# wiz16b8m4ct3_0_WIZ16B8M4CT3 register map
Vendor: Texas Instruments
Registers are 32-bit, read-write, reset 0x0 unless marked. A register's access mark holds for its fields unless they carry their own. Offsets are as the file gives them; [hi:lo] are bit positions.

## wiz16b8m4ct3_0_WIZ16B8M4CT3 (part 9 of 12)
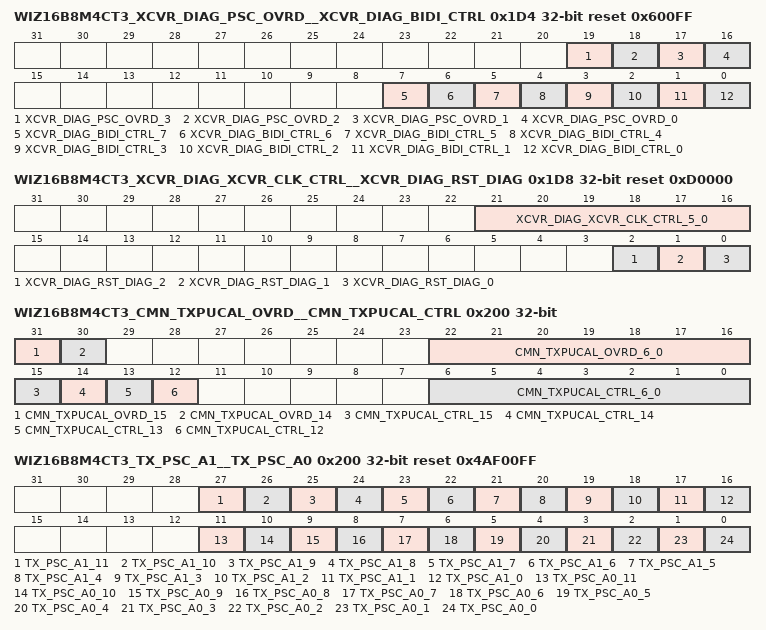
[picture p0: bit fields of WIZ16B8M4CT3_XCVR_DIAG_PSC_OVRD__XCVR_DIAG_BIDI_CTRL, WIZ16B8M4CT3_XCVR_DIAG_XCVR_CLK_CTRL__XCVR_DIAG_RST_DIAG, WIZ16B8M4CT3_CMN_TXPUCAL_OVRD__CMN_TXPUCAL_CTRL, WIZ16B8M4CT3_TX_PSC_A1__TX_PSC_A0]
0x1D4 WIZ16B8M4CT3_XCVR_DIAG_PSC_OVRD__XCVR_DIAG_BIDI_CTRL reset 0x600FF
  [19] XCVR_DIAG_PSC_OVRD_3 — Receiver DFE enable mask value standard mode 3: This bit will controls the rx_dfe_eq_enable_std_mask digital signal, which can be used to mask off the rxda_dfe_eq_enable signal coming from the power state controller and going into the analog, when xcvr_standard_mode is set to 2'b11. 1'b0 : The signal will be masked off. 1'b1 : The signal to pass through unchanged.
  [18] XCVR_DIAG_PSC_OVRD_2 — Receiver DFE enable mask value standard mode 2: This bit will controls the rx_dfe_eq_enable_std_mask digital signal, which can be used to mask off the rxda_dfe_eq_enable signal coming from the power state controller and going into the analog, when xcvr_standard_mode is set to 2'b10. 1'b0 : The signal will be masked off. 1'b1 : The signal to pass through unchanged.
  [17] XCVR_DIAG_PSC_OVRD_1 — Receiver DFE enable mask value standard mode 1: This bit will controls the rx_dfe_eq_enable_std_mask digital signal, which can be used to mask off the rxda_dfe_eq_enable signal coming from the power state controller and going into the analog, when xcvr_standard_mode is set to 2'b01. 1'b0 : The signal will be masked off. 1'b1 : The signal to pass through unchanged.
  [16] XCVR_DIAG_PSC_OVRD_0 — Receiver DFE enable mask value standard mode 0: This bit will controls the rx_dfe_eq_enable_std_mask digital signal, which can be used to mask off the rxda_dfe_eq_enable signal coming from the power state controller and going into the analog, when xcvr_standard_mode is set to 2'b00. 1'b0 : The signal will be masked off. 1'b1 : The signal to pass through unchanged.
  [7] XCVR_DIAG_BIDI_CTRL_7 — Receiver enable standard mode 3: When bidirectional bumps are implemented in the transceiver, this bit is a global enable for the receiver function, when xcvr_standard_mode is set to 2'b11. When bidirectional bumps are not implemented, this bit will be reset to 1'b1, and should not be changed. When bidirectional bumps are implemented in the transceiver, this bit and the corresponding transmitter enable bit must not be set to 1'b1 at the same time. 1'b0 : RX disabled 1'b1 : RX enabled
  [6] XCVR_DIAG_BIDI_CTRL_6 — Receiver enable standard mode 2: When bidirectional bumps are implemented in the transceiver, this bit is a global enable for the receiver function, when xcvr_standard_mode is set to 2'b10. When bidirectional bumps are not implemented, this bit will be reset to 1'b1, and should not be changed. When bidirectional bumps are implemented in the transceiver, this bit and the corresponding transmitter enable bit must not be set to 1'b1 at the same time. 1'b0 : RX disabled 1'b1 : RX enabled
  [5] XCVR_DIAG_BIDI_CTRL_5 — Receiver enable standard mode 1: When bidirectional bumps are implemented in the transceiver, this bit is a global enable for the receiver function, when xcvr_standard_mode is set to 2'b01. When bidirectional bumps are not implemented, this bit will be reset to 1'b1, and should not be changed. When bidirectional bumps are implemented in the transceiver, this bit and the corresponding transmitter enable bit must not be set to 1'b1 at the same time. 1'b0 : RX disabled 1'b1 : RX enabled
  [4] XCVR_DIAG_BIDI_CTRL_4 — Receiver enable standard mode 0: When bidirectional bumps are implemented in the transceiver, this bit is a global enable for the receiver function, when xcvr_standard_mode is set to 2'b00. When bidirectional bumps are not implemented, this bit will be reset to 1'b1, and should not be changed. When bidirectional bumps are implemented in the transceiver, this bit and the corresponding transmitter enable bit must not be set to 1'b1 at the same time. 1'b0 : RX disabled 1'b1 : RX enabled
  [3] XCVR_DIAG_BIDI_CTRL_3 — Transmitter enable standard mode 3: When bidirectional bumps are implemented in the transceiver, this bit is a global enable for the transmitter function, when xcvr_standard_mode is set to 2'b11. When bidirectional bumps are not implemented, this bit will be reset to 1'b1, and should not be changed. When bidirectional bumps are implemented in the transceiver, this bit and the corresponding receiver enable bit must not be set to 1'b1 at the same time. 1'b0 : TX disabled 1'b1 : TX enabled
  [2] XCVR_DIAG_BIDI_CTRL_2 — Transmitter enable standard mode 2: When bidirectional bumps are implemented in the transceiver, this bit is a global enable for the transmitter function, when xcvr_standard_mode is set to 2'b10. When bidirectional bumps are not implemented, this bit will be reset to 1'b1, and should not be changed. When bidirectional bumps are implemented in the transceiver, this bit and the corresponding receiver enable bit must not be set to 1'b1 at the same time. 1'b0 : TX disabled 1'b1 : TX enabled
  [1] XCVR_DIAG_BIDI_CTRL_1 — Transmitter enable standard mode 1: When bidirectional bumps are implemented in the transceiver, this bit is a global enable for the transmitter function, when xcvr_standard_mode is set to 2'b01. When bidirectional bumps are not implemented, this bit will be reset to 1'b1, and should not be changed. When bidirectional bumps are implemented in the transceiver, this bit and the corresponding receiver enable bit must not be set to 1'b1 at the same time. 1'b0 : TX disabled 1'b1 : TX enabled
  [0] XCVR_DIAG_BIDI_CTRL_0 — Transmitter enable standard mode 0: When bidirectional bumps are implemented in the transceiver, this bit is a global enable for the transmitter function, when xcvr_standard_mode is set to 2'b00. When bidirectional bumps are not implemented, this bit will be reset to 1'b1, and should not be changed. When bidirectional bumps are implemented in the transceiver, this bit and the corresponding receiver enable bit must not be set to 1'b1 at the same time. 1'b0 : TX disabled 1'b1 : TX enabled
0x1D8 WIZ16B8M4CT3_XCVR_DIAG_XCVR_CLK_CTRL__XCVR_DIAG_RST_DIAG access per field reset 0xD0000
  [21:16] XCVR_DIAG_XCVR_CLK_CTRL_5_0 rw — Transceiver clock enable delay timer value: This specifies the number of xcvr_psm_clk clock cycles that the transceiver high speed clock reset release state machine will wait between when it drives the analog transceiver clock enable signal active, and when it will initiate the process to release the reset for this clock. The default value of this register corresponds to a delay of at least 100 nSec.
  [2] XCVR_DIAG_RST_DIAG_2 ro — Current state of the tx_coef_calc_reset_n reset.
  [1] XCVR_DIAG_RST_DIAG_1 ro — Current state of the xcvr_psm_reset_n reset.
  [0] XCVR_DIAG_RST_DIAG_0 ro — Current state of the xcvr_ref_clk_reset_n reset.
0x1DC WIZ16B8M4CT3_XCVR_DIAG_DCYA
  [31:16] XCVR_DIAG_DCYA_15_0 — Reserved - spare
0x1F8 WIZ16B8M4CT3_DTB_MUX_SEL
  [4:0] DTB_MUX_SEL — See cadence documentation on digital test bus.
0x1FC WIZ16B8M4CT3_DIAG_TEST
  [31:0] DIAG_REG — Diagnostic register. This register allows full read/write of all data bits to be tested.
0x200 WIZ16B8M4CT3_CMN_TXPUCAL_OVRD__CMN_TXPUCAL_CTRL access per field
  [31] CMN_TXPUCAL_OVRD_15 rw — Resistor code override enable: Activation (1'b1) of this register bit allows the resistor codes determined during the automatic resistor calibration process to be overridden. The override value is specified using the resistor code override value field of this register.
  [30] CMN_TXPUCAL_OVRD_14 rw — Analog calibration enable override: Activation (1'b1) of this register bit will force the analog calibration circuits to be enabled by activating the cmnda_rescal_en_tx_useg enable and the cmnda_rescal_clk_tx_useg clock.
  [22:16] CMN_TXPUCAL_OVRD_6_0 rw — Resistor code override value: These bits are used to override the resistor code determined during the automatic resistor calibration process. The resistor code written to these bits is valid when the resistor code override enable bit in this register is active. The following are the values for the code. 7'b0000000: No resistors active. 7'b0000001: 1 resistor active. 7'b0000010: 2 resistors active. 7'b0000011: 3 resistors active. 7'b0000100: 4 resistors active. ... 7'b0111100: 60 resistors active. Note: The most significant bit is the calibration code sign bit, and is always 1'b0 in this application.
  [15] CMN_TXPUCAL_CTRL_15 rw — Start resistor calibration: Activating (1'b1) this bit will start the resistor calibration process. This signal must remain active until the resistor calibration process is complete. To start another resistor calibration process, this register must first be set inactive (1'b0) until the resistor calibration process done bit in this register is cleared. Note: This signal is intended to be for diagnostics purposes only. This calibration process is automatically activated internally by the startup state machine. When using this bit, the user must wait until after the internally activated process completes.
  [14] CMN_TXPUCAL_CTRL_14 ro — Resistor calibration process done: This bit will be set to 1'b1 when the resistor calibration process is complete. It will be cleared by cmn_reset_n, or by the deactivation of the start resistor calibration bit in this register after calibration is complete. Note: This bit is intended to be for diagnostics purposes only. Note: This bit is not likely to be observed as being set after internal automatic calibration is complete, because the internally generated run signal will be driven inactive immediately after the done signal is activated, and therefore the internal done signal will be cleared. Note: Three cmn_ref_clk cycles are required after the start of the resistor calibration process to clear this signal.
  [13] CMN_TXPUCAL_CTRL_13 ro — No analog calibration response : This signal indicates that the calibration function has gone through the entire calibration process, reached the final calibration value, and the analog has not responded indicating that a valid calibration value has been reached. Note: Due to the nature of the calibration process, it is not possible to determine if the analog responded or not for the lowest code of 7'b0000000. The reason for this is, when sequencing to lower codes, the calibration function is looking for the analog response to transition from 1'b1 to 1'b0. If the lowest calibration code is the correct code, the analog will respond with 1'b1, and the algorithm can't sequence to a lower code to look for the transition from 1'b1 to 1'b0. Similarly, if the analog is not responding, it is not possible to sequence to a lower code to detect this. Therefore, even when the calibration function selects this calibration code as valid, this bit will be set.
  [12] CMN_TXPUCAL_CTRL_12 ro — Current analog comparator response: This is the current state of the analog comparator response signal (cmnda_rescal_comp_tx_useg). This signal is not synchronized, and is provided for diagnostic purposes only.
  [6:0] CMN_TXPUCAL_CTRL_6_0 ro — Resistor calibration code: This is the calibration code that was determined by the resistor calibration process. The following are the values for the code. 7'b0000000: No resistors active. 7'b0000001: 1 resistor active. 7'b0000010: 2 resistors active. 7'b0000011: 3 resistors active. 7'b0000100: 4 resistors active. ... 7'b0111100: 60 resistors active. Note: The most significant bit is the calibration code sign bit, and is always 1'b0 in this application. Note: The reset value for this field is with the common calibration power island switched off. In cases where this power island is switched on, the reset value be 7'b0101101.
0x200 WIZ16B8M4CT3_TX_PSC_A1__TX_PSC_A0 reset 0x4AF00FF
  [27] TX_PSC_A1_11 — TX driver common mode enable extend control
  [26] TX_PSC_A1_10 — Force txda_lfps_sel active
  [25] TX_PSC_A1_9 — LFPS clock gate enable
  [24] TX_PSC_A1_8 — Reserved - spare
  [23] TX_PSC_A1_7 — Transmitter low current mode
  [22] TX_PSC_A1_6 — Transmitter mission mode enable
  [21] TX_PSC_A1_5 — TX driver common mode enable
  [20] TX_PSC_A1_4 — TX driver enable
  [19] TX_PSC_A1_3 — TX post-emphasis enable (C+1)
  [18] TX_PSC_A1_2 — TX pre-emphasis enable (C-1)
  [17] TX_PSC_A1_1 — TX pre-driver enable
  [16] TX_PSC_A1_0 — TX serializer enable
  [11] TX_PSC_A0_11 — TX driver common mode enable extend control: Specifies which power states the tx_cmn_mode_en_ext signal is considered valid in and can be used to force the driver to continue to be in the common mode state.
  [10] TX_PSC_A0_10 — Force txda_lfps_sel active: Setting this bit forces the txda_lfps_sel signal going to the analog to be driven active. Note: This function is implemented for additional power savings. In the analog, this signal controls a MUX select associated with the driver. Setting this bit to 1'b1 will force the MUX to select the LFPS data path. By selecting this path in low power states, instead of the serializer path, the driver inputs will be driven to 1'b0, instead of having the potential to toggle.
  [9] TX_PSC_A0_9 — LFPS clock gate enable: Enables the LFPS clock gate when an LFPS clock is required.
  [8] TX_PSC_A0_8 — Reserved - spare
  [7] TX_PSC_A0_7 — Transmitter low current mode: Enables a low current consumption mode within the common mode voltage circuit in the driver, via the txda_drv_idle_lowi_en signal going to the analog.
  [6] TX_PSC_A0_6 — Transmitter mission mode enable: Enables the analog circuits in the driver required to run in mission mode, via the txda_drv_mission_en signal going to the analog.
  [5] TX_PSC_A0_5 — TX driver common mode enable: Enables the common mode voltage circuits in the driver.
  [4] TX_PSC_A0_4 — TX driver enable: Enables the transmitter driver, via the H bridge driver controller.
  [3] TX_PSC_A0_3 — TX post-emphasis enable (C+1): Enables the transmitter circuits related to the post-emphasis function.
  [2] TX_PSC_A0_2 — TX pre-emphasis enable (C-1): Enables the transmitter circuits related to the pre-emphasis function.
  [1] TX_PSC_A0_1 — TX pre-driver enable: Enables the transmitter pre-driver, driver data selection MUX, and receiver detect.
  [0] TX_PSC_A0_0 — TX serializer enable: Enables the serializer and related clock divider circuits.
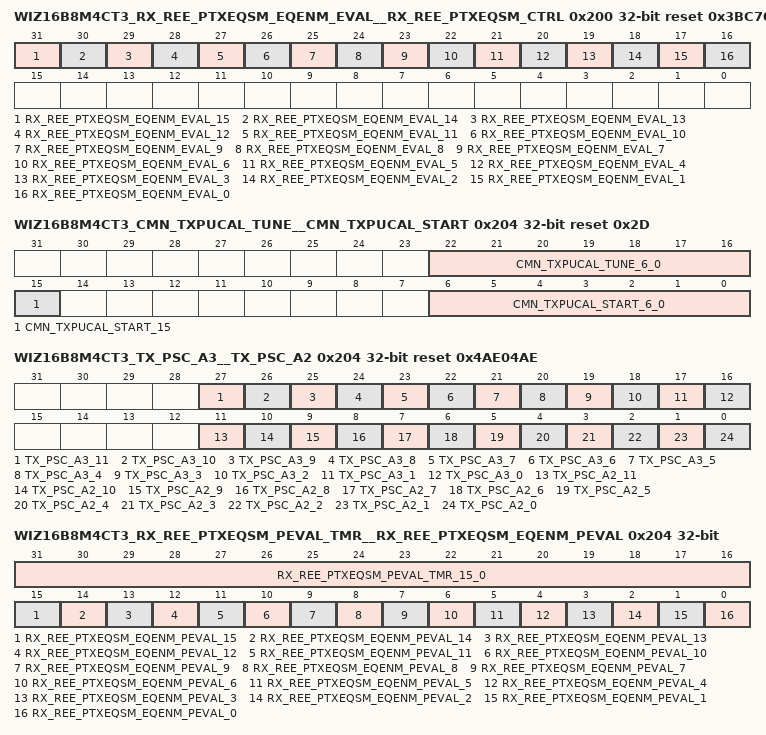
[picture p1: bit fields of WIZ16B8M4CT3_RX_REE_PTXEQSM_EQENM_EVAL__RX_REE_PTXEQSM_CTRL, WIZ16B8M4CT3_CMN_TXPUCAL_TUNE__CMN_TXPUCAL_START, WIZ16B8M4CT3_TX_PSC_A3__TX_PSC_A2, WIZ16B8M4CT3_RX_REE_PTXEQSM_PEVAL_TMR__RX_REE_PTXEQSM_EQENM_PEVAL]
0x200 WIZ16B8M4CT3_RX_REE_PTXEQSM_EQENM_EVAL__RX_REE_PTXEQSM_CTRL reset 0x3BC70000
  [31] RX_REE_PTXEQSM_EQENM_EVAL_15 — Reserved - spare
  [30] RX_REE_PTXEQSM_EQENM_EVAL_14 — Ignore 1010 controller : When set to 1'b1, this function is enabled when the PCIe TX equalization control state machine is controlling the REE.
  [29] RX_REE_PTXEQSM_EQENM_EVAL_13 — TX equalization evaluator : When set to 1'b1, this function is enabled when the PCIe TX equalization control state machine is controlling the REE.
  [28] RX_REE_PTXEQSM_EQENM_EVAL_12 — TX post cursor control : When set to 1'b1, this function is enabled when the PCIe TX equalization control state machine is controlling the REE.
  [27] RX_REE_PTXEQSM_EQENM_EVAL_11 — TX pre cursor control : When set to 1'b1, this function is enabled when the PCIe TX equalization control state machine is controlling the REE.
  [26] RX_REE_PTXEQSM_EQENM_EVAL_10 — Short channel correction : When set to 1'b1, this function is enabled when the TX equalization general control state machine is controlling the REE.
  [25] RX_REE_PTXEQSM_EQENM_EVAL_9 — RX attenuation : When set to 1'b1, this function is enabled when the PCIe TX equalization control state machine is controlling the REE.
  [24] RX_REE_PTXEQSM_EQENM_EVAL_8 — RX VGA gain : When set to 1'b1, this function is enabled when the PCIe TX equalization control state machine is controlling the REE.
  [23] RX_REE_PTXEQSM_EQENM_EVAL_7 — RX offset correction coefficient : When set to 1'b1, this function is enabled when the PCIe TX equalization control state machine is controlling the REE.
  [22] RX_REE_PTXEQSM_EQENM_EVAL_6 — RX peaking amp gain : When set to 1'b1, this function is enabled when the PCIe TX equalization control state machine is controlling the REE.
  [21] RX_REE_PTXEQSM_EQENM_EVAL_5 — RX low frequency equalizer adaptive control : When set to 1'b1, this function is enabled when the PCIe TX equalization control state machine is controlling the REE.
  [20] RX_REE_PTXEQSM_EQENM_EVAL_4 — Reserved - spare
  [19] RX_REE_PTXEQSM_EQENM_EVAL_3 — Reserved - spare
  [18] RX_REE_PTXEQSM_EQENM_EVAL_2 — RX tap 3 : When set to 1'b1, this function is enabled when the PCIe TX equalization control state machine is controlling the REE.
  [17] RX_REE_PTXEQSM_EQENM_EVAL_1 — RX tap 2 : When set to 1'b1, this function is enabled when the PCIe TX equalization control state machine is controlling the REE.
  [16] RX_REE_PTXEQSM_EQENM_EVAL_0 — RX tap 1 : When set to 1'b1, this function is enabled when the PCIe TX equalization control state machine is controlling the REE.
0x204 WIZ16B8M4CT3_CMN_TXPUCAL_TUNE__CMN_TXPUCAL_START reset 0x2D
  [22:16] CMN_TXPUCAL_TUNE_6_0 — Resistor calibration tune value: The value of this field is added to the automatically calibrated code, or the override code if override is enabled. Note: This value is a twos complement value, so the calibrated code can be increased or decreased.
  [15] CMN_TXPUCAL_START_15 — Resistor calibration direction: This controls the direction that the automatic calibration process steps the calibration codes in. 1'b0 : From 7'b0000000 to 7'b0111100. 1'b1 : From 7'b0111100 to 7'b0000000.
  [6:0] CMN_TXPUCAL_START_6_0 — Start resistor calibration code: This is the calibration code that the resistor calibration process starts with when automatic calibration is run. The following are the values for the code. 7'b0000000: No resistors active. 7'b0000001: 1 resistor active. 7'b0000010: 2 resistors active. 7'b0000011: 3 resistors active. 7'b0000100: 4 resistors active. ... 7'b0111100: 60 resistors active. Note: The most significant bit is the calibration code sign bit, and is always 1'b0 in this application.
0x204 WIZ16B8M4CT3_TX_PSC_A3__TX_PSC_A2 reset 0x4AE04AE
  [27] TX_PSC_A3_11 — TX driver common mode enable extend control
  [26] TX_PSC_A3_10 — Force txda_lfps_sel active
  [25] TX_PSC_A3_9 — LFPS clock gate enable
  [24] TX_PSC_A3_8 — Reserved - spare
  [23] TX_PSC_A3_7 — Transmitter low current mode
  [22] TX_PSC_A3_6 — Transmitter mission mode enable
  [21] TX_PSC_A3_5 — TX driver common mode enable
  [20] TX_PSC_A3_4 — TX driver enable
  [19] TX_PSC_A3_3 — TX post-emphasis enable (C+1)
  [18] TX_PSC_A3_2 — TX pre-emphasis enable (C-1)
  [17] TX_PSC_A3_1 — TX pre-driver enable
  [16] TX_PSC_A3_0 — TX serializer enable
  [11] TX_PSC_A2_11 — TX driver common mode enable extend control
  [10] TX_PSC_A2_10 — Force txda_lfps_sel active
  [9] TX_PSC_A2_9 — LFPS clock gate enable
  [8] TX_PSC_A2_8 — Reserved - spare
  [7] TX_PSC_A2_7 — Transmitter low current mode
  [6] TX_PSC_A2_6 — Transmitter mission mode enable
  [5] TX_PSC_A2_5 — TX driver common mode enable
  [4] TX_PSC_A2_4 — TX driver enable
  [3] TX_PSC_A2_3 — TX post-emphasis enable (C+1)
  [2] TX_PSC_A2_2 — TX pre-emphasis enable (C-1)
  [1] TX_PSC_A2_1 — TX pre-driver enable
  [0] TX_PSC_A2_0 — TX serializer enable
0x204 WIZ16B8M4CT3_RX_REE_PTXEQSM_PEVAL_TMR__RX_REE_PTXEQSM_EQENM_PEVAL
  [31:16] RX_REE_PTXEQSM_PEVAL_TMR_15_0 — Run post evaluation equalization timer value : This specifies number of clock cycles the state machine will wait in the Post Evaluation Equalization state.
  [15] RX_REE_PTXEQSM_EQENM_PEVAL_15 — Reserved - spare
  [14] RX_REE_PTXEQSM_EQENM_PEVAL_14 — Ignore 1010 controller : When set to 1'b1, this function is enabled when the PCIe TX equalization control state machine is controlling the REE.
  [13] RX_REE_PTXEQSM_EQENM_PEVAL_13 — TX equalization evaluator : When set to 1'b1, this function is enabled when the PCIe TX equalization control state machine is controlling the REE.
  [12] RX_REE_PTXEQSM_EQENM_PEVAL_12 — TX post cursor control : When set to 1'b1, this function is enabled when the PCIe TX equalization control state machine is controlling the REE.
  [11] RX_REE_PTXEQSM_EQENM_PEVAL_11 — TX pre cursor control : When set to 1'b1, this function is enabled when the PCIe TX equalization control state machine is controlling the REE.
  [10] RX_REE_PTXEQSM_EQENM_PEVAL_10 — Short channel correction : When set to 1'b1, this function is enabled when the TX equalization general control state machine is controlling the REE.
  [9] RX_REE_PTXEQSM_EQENM_PEVAL_9 — RX attenuation : When set to 1'b1, this function is enabled when the PCIe TX equalization control state machine is controlling the REE.
  [8] RX_REE_PTXEQSM_EQENM_PEVAL_8 — RX VGA gain : When set to 1'b1, this function is enabled when the PCIe TX equalization control state machine is controlling the REE.
  [7] RX_REE_PTXEQSM_EQENM_PEVAL_7 — RX offset correction coefficient : When set to 1'b1, this function is enabled when the PCIe TX equalization control state machine is controlling the REE.
  [6] RX_REE_PTXEQSM_EQENM_PEVAL_6 — RX peaking amp gain : When set to 1'b1, this function is enabled when the PCIe TX equalization control state machine is controlling the REE.
  [5] RX_REE_PTXEQSM_EQENM_PEVAL_5 — RX low frequency equalizer adaptive control : When set to 1'b1, this function is enabled when the PCIe TX equalization control state machine is controlling the REE.
  [4] RX_REE_PTXEQSM_EQENM_PEVAL_4 — Reserved - spare
  [3] RX_REE_PTXEQSM_EQENM_PEVAL_3 — Reserved - spare
  [2] RX_REE_PTXEQSM_EQENM_PEVAL_2 — RX tap 3 : When set to 1'b1, this function is enabled when the PCIe TX equalization control state machine is controlling the REE.
  [1] RX_REE_PTXEQSM_EQENM_PEVAL_1 — RX tap 2 : When set to 1'b1, this function is enabled when the PCIe TX equalization control state machine is controlling the REE.
  [0] RX_REE_PTXEQSM_EQENM_PEVAL_0 — RX tap 1 : When set to 1'b1, this function is enabled when the PCIe TX equalization control state machine is controlling the REE.
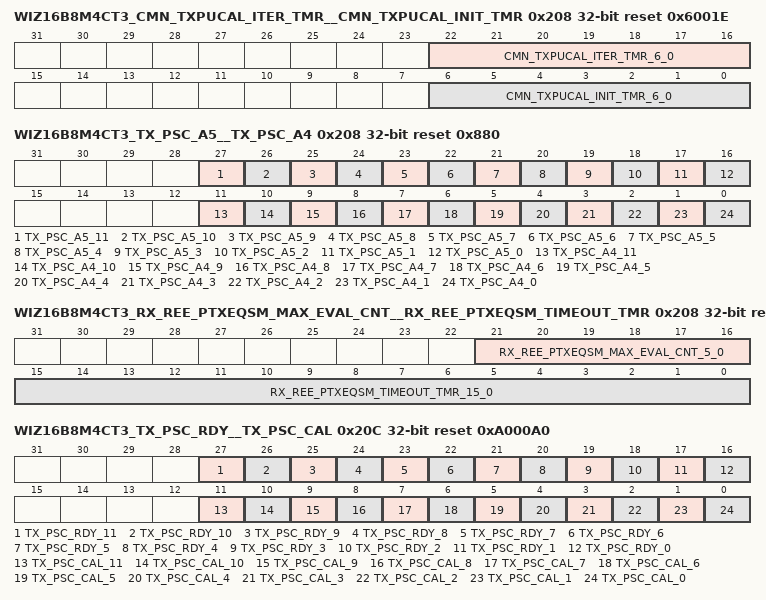
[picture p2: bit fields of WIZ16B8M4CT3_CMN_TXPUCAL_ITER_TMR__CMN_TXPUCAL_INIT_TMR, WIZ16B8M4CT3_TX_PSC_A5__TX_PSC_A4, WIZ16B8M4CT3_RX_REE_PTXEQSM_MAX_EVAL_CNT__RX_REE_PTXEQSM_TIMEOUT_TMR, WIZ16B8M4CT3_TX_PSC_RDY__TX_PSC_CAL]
0x208 WIZ16B8M4CT3_CMN_TXPUCAL_ITER_TMR__CMN_TXPUCAL_INIT_TMR reset 0x6001E
  [22:16] CMN_TXPUCAL_ITER_TMR_6_0 — Iteration wait timer value: This is the number of cmn_ref_clk clocks to wait between when a value is placed on the resistor selection bus going to the analog, and when the comparator value coming from the analog circuits can be checked. Note: This results in the minimum number of cmn_ref_clk clocks required to wait 240 nSec. Note: This should never be set to a value of less than 3.
  [6:0] CMN_TXPUCAL_INIT_TMR_6_0 — Initialization wait timer value: This is the number of cmn_ref_clk clocks to wait between when the analog resistor calibration circuits are enabled, and when the first resistor selection values are placed on the resistor selection bus, going to the analog. Note: This results in the minimum number of cmn_ref_clk clocks required to wait 1.2 uSec. Note: This should never be set to a value of less than 1.
0x208 WIZ16B8M4CT3_TX_PSC_A5__TX_PSC_A4 reset 0x880
  [27] TX_PSC_A5_11 — TX driver common mode enable extend control
  [26] TX_PSC_A5_10 — Force txda_lfps_sel active
  [25] TX_PSC_A5_9 — LFPS clock gate enable
  [24] TX_PSC_A5_8 — Reserved - spare
  [23] TX_PSC_A5_7 — Transmitter low current mode
  [22] TX_PSC_A5_6 — Transmitter mission mode enable
  [21] TX_PSC_A5_5 — TX driver common mode enable
  [20] TX_PSC_A5_4 — TX driver enable
  [19] TX_PSC_A5_3 — TX post-emphasis enable (C+1)
  [18] TX_PSC_A5_2 — TX pre-emphasis enable (C-1)
  [17] TX_PSC_A5_1 — TX pre-driver enable
  [16] TX_PSC_A5_0 — TX serializer enable
  [11] TX_PSC_A4_11 — TX driver common mode enable extend control
  [10] TX_PSC_A4_10 — Force txda_lfps_sel active
  [9] TX_PSC_A4_9 — LFPS clock gate enable
  [8] TX_PSC_A4_8 — Reserved - spare
  [7] TX_PSC_A4_7 — Transmitter low current mode
  [6] TX_PSC_A4_6 — Transmitter mission mode enable
  [5] TX_PSC_A4_5 — TX driver common mode enable
  [4] TX_PSC_A4_4 — TX driver enable
  [3] TX_PSC_A4_3 — TX post-emphasis enable (C+1)
  [2] TX_PSC_A4_2 — TX pre-emphasis enable (C-1)
  [1] TX_PSC_A4_1 — TX pre-driver enable
  [0] TX_PSC_A4_0 — TX serializer enable
0x208 WIZ16B8M4CT3_RX_REE_PTXEQSM_MAX_EVAL_CNT__RX_REE_PTXEQSM_TIMEOUT_TMR reset 0x3F30D4
  [21:16] RX_REE_PTXEQSM_MAX_EVAL_CNT_5_0 — Incremental evaluation counter load value: This is the maximum number of incremental evaluations that will be performed plus one. When the number of incremental evaluations specified here minus one are performed, the state machine will indicate that no further equalization processes are required.
  [15:0] RX_REE_PTXEQSM_TIMEOUT_TMR_15_0 — Time-out timer load value: This specifies the number of clocks to run a PCIe evaluation before a time-out is indicated. If a time-out takes place, the state machine will indicate that no further equalization processes are required. Note: This value is shifted left 4 bits when loading the timer, the actual time is 16X this value.
0x20C WIZ16B8M4CT3_TX_PSC_RDY__TX_PSC_CAL reset 0xA000A0
  [27] TX_PSC_RDY_11 — TX driver common mode enable extend control
  [26] TX_PSC_RDY_10 — Force txda_lfps_sel active
  [25] TX_PSC_RDY_9 — LFPS clock gate enable
  [24] TX_PSC_RDY_8 — Reserved - spare
  [23] TX_PSC_RDY_7 — Transmitter low current mode
  [22] TX_PSC_RDY_6 — Transmitter mission mode enable
  [21] TX_PSC_RDY_5 — TX driver common mode enable
  [20] TX_PSC_RDY_4 — TX driver enable
  [19] TX_PSC_RDY_3 — TX post-emphasis enable (C+1)
  [18] TX_PSC_RDY_2 — TX pre-emphasis enable (C-1)
  [17] TX_PSC_RDY_1 — TX pre-driver enable
  [16] TX_PSC_RDY_0 — TX serializer enable
  [11] TX_PSC_CAL_11 — TX driver common mode enable extend control
  [10] TX_PSC_CAL_10 — Force txda_lfps_sel active
  [9] TX_PSC_CAL_9 — LFPS clock gate enable
  [8] TX_PSC_CAL_8 — Reserved - spare
  [7] TX_PSC_CAL_7 — Transmitter low current mode
  [6] TX_PSC_CAL_6 — Transmitter mission mode enable
  [5] TX_PSC_CAL_5 — TX driver common mode enable
  [4] TX_PSC_CAL_4 — TX driver enable
  [3] TX_PSC_CAL_3 — TX post-emphasis enable (C+1)
  [2] TX_PSC_CAL_2 — TX pre-emphasis enable (C-1)
  [1] TX_PSC_CAL_1 — TX pre-driver enable
  [0] TX_PSC_CAL_0 — TX serializer enable
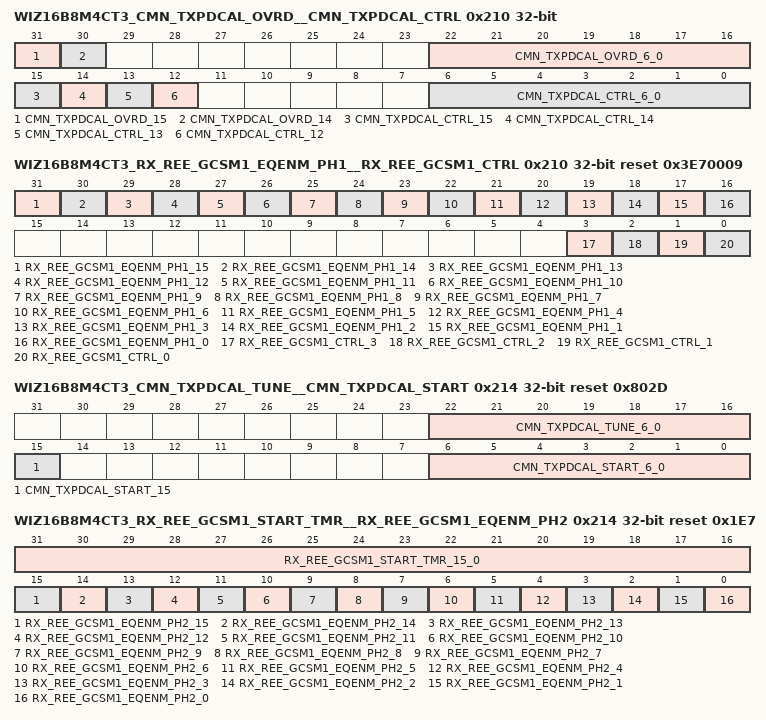
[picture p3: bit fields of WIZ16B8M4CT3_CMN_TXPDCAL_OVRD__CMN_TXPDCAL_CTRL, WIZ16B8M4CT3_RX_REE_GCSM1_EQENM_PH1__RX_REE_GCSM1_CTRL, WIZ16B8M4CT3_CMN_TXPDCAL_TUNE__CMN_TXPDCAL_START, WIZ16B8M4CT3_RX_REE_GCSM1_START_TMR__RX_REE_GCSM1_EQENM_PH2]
0x210 WIZ16B8M4CT3_CMN_TXPDCAL_OVRD__CMN_TXPDCAL_CTRL access per field
  [31] CMN_TXPDCAL_OVRD_15 rw — Resistor code override enable: Activation (1'b1) of this register bit allows the resistor codes determined during the automatic resistor calibration process to be overridden. The override value is specified using the resistor code override value field of this register.
  [30] CMN_TXPDCAL_OVRD_14 rw — Analog calibration enable override: Activation (1'b1) of this register bit will force the analog calibration circuits to be enabled by activating the cmnda_rescal_en_tx_dseg enable and the cmnda_rescal_clk_tx_dseg clock.
  [22:16] CMN_TXPDCAL_OVRD_6_0 rw — Resistor code override value: These bits are used to override the resistor code determined during the automatic resistor calibration process. The resistor code written to these bits is valid when the resistor code override enable bit in this register is active. The following are the values for the code. 7'b0000000: No resistors active. 7'b0000001: 1 resistor active. 7'b0000010: 2 resistors active. 7'b0000011: 3 resistors active. 7'b0000100: 4 resistors active. ... 7'b0111100: 60 resistors active. Note: The most significant bit is the calibration code sign bit, and is always 1'b0 in this application.
  [15] CMN_TXPDCAL_CTRL_15 rw — Start resistor calibration: Activating (1'b1) this bit will start the resistor calibration process. This signal must remain active until the resistor calibration process is complete. To start another resistor calibration process, this register must first be set inactive (1'b0) until the resistor calibration process done bit in this register is cleared. Note: This signal is intended to be for diagnostics purposes only. This calibration process is automatically activated internally by the startup state machine. When using this bit, the user must wait until after the internally activated process completes.
  [14] CMN_TXPDCAL_CTRL_14 ro — Resistor calibration process done: This bit will be set to 1'b1 when the resistor calibration process is complete. It will be cleared by cmn_reset_n, or by the deactivation of the start resistor calibration bit in this register after calibration is complete. Note: This bit is intended to be for diagnostics purposes only. Note: This bit is not likely to be observed as being set after internal automatic calibration is complete, because the internally generated run signal will be driven inactive immediately after the done signal is activated, and therefore the internal done signal will be cleared. Note: Three cmn_ref_clk cycles are required after the start of the resistor calibration process to clear this signal.
  [13] CMN_TXPDCAL_CTRL_13 ro — No analog calibration response : This signal indicates that the calibration function has gone through the entire calibration process, reached the final calibration value, and the analog has not responded indicating that a valid calibration value has been reached. Note: Due to the nature of the calibration process, it is not possible to determine if the analog responded or not for the lowest code of 7'b0000000. The reason for this is, when sequencing to lower codes, the calibration function is looking for the analog response to transition from 1'b1 to 1'b0. If the lowest calibration code is the correct code, the analog will respond with 1'b1, and the algorithm can't sequence to a lower code to look for the transition from 1'b1 to 1'b0. Similarly, if the analog is not responding, it is not possible to sequence to a lower code to detect this. Therefore, even when the calibration function selects this calibration code as valid, this bit will be set.
  [12] CMN_TXPDCAL_CTRL_12 ro — Current analog comparator response: This is the current state of the analog comparator response signal (cmnda_rescal_comp_tx_dseg). This signal is not synchronized, and is provided for diagnostic purposes only.
  [6:0] CMN_TXPDCAL_CTRL_6_0 ro — Resistor calibration code: This is the calibration code that was determined by the resistor calibration process. The following are the values for the code. 7'b0000000: No resistors active. 7'b0000001: 1 resistor active. 7'b0000010: 2 resistors active. 7'b0000011: 3 resistors active. 7'b0000100: 4 resistors active. ... 7'b0111100: 60 resistors active. Note: The most significant bit is the calibration code sign bit, and is always 1'b0 in this application. Note: The reset value for this field is with the common calibration power island switched off. In cases where this power island is switched on, the reset value be 7'b0101101.
0x210 WIZ16B8M4CT3_RX_REE_GCSM1_EQENM_PH1__RX_REE_GCSM1_CTRL reset 0x3E70009
  [31] RX_REE_GCSM1_EQENM_PH1_15 — Reserved - spare
  [30] RX_REE_GCSM1_EQENM_PH1_14 — Ignore 1010 controller : When set to 1'b1, this function is enabled when the general control state machine 1 is controlling the REE.
  [29] RX_REE_GCSM1_EQENM_PH1_13 — TX equalization evaluator : When set to 1'b1, this function is enabled when the general control state machine 1 is controlling the REE.
  [28] RX_REE_GCSM1_EQENM_PH1_12 — TX post cursor control : When set to 1'b1, this function is enabled when the general control state machine 1 is controlling the REE.
  [27] RX_REE_GCSM1_EQENM_PH1_11 — TX pre cursor control : When set to 1'b1, this function is enabled when the general control state machine 1 is controlling the REE.
  [26] RX_REE_GCSM1_EQENM_PH1_10 — Short channel correction : When set to 1'b1, this function is enabled when the general control state machine 1 is controlling the REE.
  [25] RX_REE_GCSM1_EQENM_PH1_9 — RX attenuation : When set to 1'b1, this function is enabled when the general control state machine 1 is controlling the REE.
  [24] RX_REE_GCSM1_EQENM_PH1_8 — RX VGA gain : When set to 1'b1, this function is enabled when the general control state machine 1 is controlling the REE.
  [23] RX_REE_GCSM1_EQENM_PH1_7 — RX offset correction coefficient : When set to 1'b1, this function is enabled when the general control state machine 1 is controlling the REE.
  [22] RX_REE_GCSM1_EQENM_PH1_6 — RX peaking amp gain : When set to 1'b1, this function is enabled when the general control state machine 1 is controlling the REE.
  [21] RX_REE_GCSM1_EQENM_PH1_5 — RX low frequency equalizer adaptive control : When set to 1'b1, this function is enabled when the general control state machine 1 is controlling the REE.
  [20] RX_REE_GCSM1_EQENM_PH1_4 — Reserved - spare
  [19] RX_REE_GCSM1_EQENM_PH1_3 — Reserved - spare
  [18] RX_REE_GCSM1_EQENM_PH1_2 — RX tap 3 : When set to 1'b1, this function is enabled when the general control state machine 1 is controlling the REE.
  [17] RX_REE_GCSM1_EQENM_PH1_1 — RX tap 2 : When set to 1'b1, this function is enabled when the general control state machine 1 is controlling the REE.
  [16] RX_REE_GCSM1_EQENM_PH1_0 — RX tap 1 : When set to 1'b1, this function is enabled when the general control state machine 1 is controlling the REE.
  [3] RX_REE_GCSM1_CTRL_3 — Equalization function reset enable: Enables the reset of the functions controlled by this state machine, using the rx_ree_fcn_reset_n signal, when the equalization mode changes. 1'b1 : Enabled 1'b0 : Disabled
  [2] RX_REE_GCSM1_CTRL_2 — Loop enable: Controls when the equalization functions in this state machine are run one time or loop continuously.
  [1] RX_REE_GCSM1_CTRL_1 — Force run equalization: Setting this bit to a 1'b1, will force the general control state machine to run, independent of the macro functions that normally run the equalization.
  [0] RX_REE_GCSM1_CTRL_0 — Enable: This bit enables the general control state machine function. 1'b1 : Enabled 1'b0 : Disabled
0x214 WIZ16B8M4CT3_CMN_TXPDCAL_TUNE__CMN_TXPDCAL_START reset 0x802D
  [22:16] CMN_TXPDCAL_TUNE_6_0 — Resistor calibration tune value: The value of this field is added to the automatically calibrated code, or the override code if override is enabled. Note: This value is a twos complement value, so the calibrated code can be increased or decreased.
  [15] CMN_TXPDCAL_START_15 — Resistor calibration direction: This controls the direction that the automatic calibration process steps the calibration codes in. 1'b0 : From 7'b0000000 to 7'b0111100. 1'b1 : From 7'b0111100 to 7'b0000000.
  [6:0] CMN_TXPDCAL_START_6_0 — Start resistor calibration code: This is the calibration code that the resistor calibration process starts with when automatic calibration is run. The following are the values for the code. 7'b0000000: No resistors active. 7'b0000001: 1 resistor active. 7'b0000010: 2 resistors active. 7'b0000011: 3 resistors active. 7'b0000100: 4 resistors active. ... 7'b0111100: 60 resistors active. Note: The most significant bit is the calibration code sign bit, and is always 1'b0 in this application.
0x214 WIZ16B8M4CT3_RX_REE_GCSM1_START_TMR__RX_REE_GCSM1_EQENM_PH2 reset 0x1E7
  [31:16] RX_REE_GCSM1_START_TMR_15_0 — Start timer value : The number of clock cycles the state machine will wait in the Start Delay state. Note: This value is shifted left 8 bits when loading the timer, the actual time is 256X this value.
  [15] RX_REE_GCSM1_EQENM_PH2_15 — Reserved - spare
  [14] RX_REE_GCSM1_EQENM_PH2_14 — Ignore 1010 controller : When set to 1'b1, this function is enabled when the general control state machine 1 is controlling the REE.
  [13] RX_REE_GCSM1_EQENM_PH2_13 — TX equalization evaluator : When set to 1'b1, this function is enabled when the general control state machine 1 is controlling the REE.
  [12] RX_REE_GCSM1_EQENM_PH2_12 — TX post cursor control : When set to 1'b1, this function is enabled when the general control state machine 1 is controlling the REE.
  [11] RX_REE_GCSM1_EQENM_PH2_11 — TX pre cursor control : When set to 1'b1, this function is enabled when the general control state machine 1 is controlling the REE.
  [10] RX_REE_GCSM1_EQENM_PH2_10 — Short channel correction : When set to 1'b1, this function is enabled when the general control state machine 1 is controlling the REE.
  [9] RX_REE_GCSM1_EQENM_PH2_9 — RX attenuation : When set to 1'b1, this function is enabled when the general control state machine 1 is controlling the REE.
  [8] RX_REE_GCSM1_EQENM_PH2_8 — RX VGA gain : When set to 1'b1, this function is enabled when the general control state machine 1 is controlling the REE.
  [7] RX_REE_GCSM1_EQENM_PH2_7 — RX offset correction coefficient : When set to 1'b1, this function is enabled when the general control state machine 1 is controlling the REE.
  [6] RX_REE_GCSM1_EQENM_PH2_6 — RX peaking amp gain : When set to 1'b1, this function is enabled when the general control state machine 1 is controlling the REE.
  [5] RX_REE_GCSM1_EQENM_PH2_5 — RX low frequency equalizer adaptive control : When set to 1'b1, this function is enabled when the general control state machine 1 is controlling the REE.
  [4] RX_REE_GCSM1_EQENM_PH2_4 — Reserved - spare
  [3] RX_REE_GCSM1_EQENM_PH2_3 — Reserved - spare
  [2] RX_REE_GCSM1_EQENM_PH2_2 — RX tap 3 : When set to 1'b1, this function is enabled when the general control state machine 1 is controlling the REE.
  [1] RX_REE_GCSM1_EQENM_PH2_1 — RX tap 2 : When set to 1'b1, this function is enabled when the general control state machine 1 is controlling the REE.
  [0] RX_REE_GCSM1_EQENM_PH2_0 — RX tap 1 : When set to 1'b1, this function is enabled when the general control state machine 1 is controlling the REE.
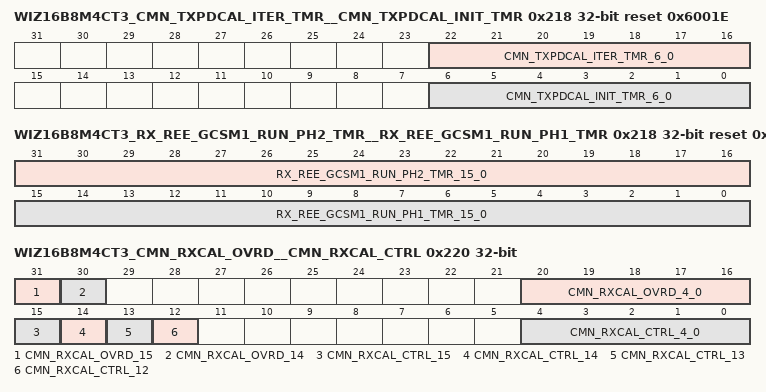
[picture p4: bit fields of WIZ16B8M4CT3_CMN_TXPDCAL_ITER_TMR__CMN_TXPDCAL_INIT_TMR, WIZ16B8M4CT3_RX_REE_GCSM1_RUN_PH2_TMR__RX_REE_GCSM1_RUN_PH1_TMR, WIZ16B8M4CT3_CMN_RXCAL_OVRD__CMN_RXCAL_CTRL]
0x218 WIZ16B8M4CT3_CMN_TXPDCAL_ITER_TMR__CMN_TXPDCAL_INIT_TMR reset 0x6001E
  [22:16] CMN_TXPDCAL_ITER_TMR_6_0 — Iteration wait timer value: This is the number of cmn_ref_clk clocks to wait between when a value is placed on the resistor selection bus going to the analog, and when the comparator value coming from the analog circuits can be checked. Note: This results in the minimum number of cmn_ref_clk clocks required to wait 240 nSec. Note: This should never be set to a value of less than 3.
  [6:0] CMN_TXPDCAL_INIT_TMR_6_0 — Initialization wait timer value: This is the number of cmn_ref_clk clocks to wait between when the analog resistor calibration circuits are enabled, and when the first resistor selection values are placed on the resistor selection bus, going to the analog. Note: This results in the minimum number of cmn_ref_clk clocks required to wait 1.2 uSec. Note: This should never be set to a value of less than 1.
0x218 WIZ16B8M4CT3_RX_REE_GCSM1_RUN_PH2_TMR__RX_REE_GCSM1_RUN_PH1_TMR reset 0x9D0F43
  [31:16] RX_REE_GCSM1_RUN_PH2_TMR_15_0 — Run phase 2 timer value : This specifies the number of clock cycles the state machine will wait in the Run Equalization Phase 2 state. Note: This value is shifted left 8 bits when loading the timer, the actual time is 256X this value.
  [15:0] RX_REE_GCSM1_RUN_PH1_TMR_15_0 — Run phase 1 timer value : This specifies the number of clock cycles the state machine will wait in the Run Equalization Phase 1 state. If this register is set to all 1s, the run in the Run Equalization Phase 1 state indefinitely. Note: This value is shifted left 8 bits when loading the timer, the actual time is 256X this value.
0x220 WIZ16B8M4CT3_CMN_RXCAL_OVRD__CMN_RXCAL_CTRL access per field
  [31] CMN_RXCAL_OVRD_15 rw — Resistor code override enable: Activation (1'b1) of this register bit allows the resistor codes determined during the automatic resistor calibration process to be overridden. The override value is specified using the resistor code override value field of this register.
  [30] CMN_RXCAL_OVRD_14 rw — Analog calibration enable override: Activation (1'b1) of this register bit will force the analog calibration circuits to be enabled by activating the cmnda_rescal_en_rx enable and the cmnda_rescal_clk_rx clock.
  [20:16] CMN_RXCAL_OVRD_4_0 rw — Resistor code override value: These bits are used to override the resistor code determined during the automatic resistor calibration process. The resistor code written to these bits is valid when the resistor code override enable bit in this register is active. The following are the values for the code: 5'b00000: No resistors active 5'b00001: 1 resistor active 5'b00010: 2 resistors active 5'b00011: 3 resistors active ... 5'b01110: 14 resistors active. 5'b01111: 15 resistors active. Note: The most significant bit is the calibration code sign bit, and is always 1'b0 in this application.
  [15] CMN_RXCAL_CTRL_15 rw — Start resistor calibration: Activating (1'b1) this bit will start the resistor calibration process. This signal must remain active until the resistor calibration process is complete. To start another resistor calibration process, this register must first be set inactive (1'b0) until the resistor calibration process done bit in this register is cleared. Note: This signal is intended to be for diagnostics purposes only. This calibration process is automatically activated internally by the startup state machine. When using this bit, the user must wait until after the internally activated process completes.
  [14] CMN_RXCAL_CTRL_14 ro — Resistor calibration process done: This bit will be set to 1'b1 when the resistor calibration process is complete. It will be cleared by cmn_reset_n, or by the deactivation of the start resistor calibration bit in this register after calibration is complete. Note: This bit is intended to be for diagnostics purposes only. Note: This bit is not likely to be observed as being set after internal automatic calibration is complete, because the internally generated run signal will be driven inactive immediately after the done signal is activated, and therefore the internal done signal will be cleared. Note: Three cmn_ref_clk cycles are required after the start of the resistor calibration process to clear this signal.
  [13] CMN_RXCAL_CTRL_13 ro — No analog calibration response : This signal indicates that the calibration function has gone through the entire calibration process, reached the final calibration value, and the analog has not responded indicating that a valid calibration value has been reached. Note: Due to the nature of the calibration process, it is not possible to determine if the analog responded or not for the lowest code of 5'b00000. The reason for this is, when sequencing to lower codes, the calibration function is looking for the analog response to transition from 1'b1 to 1'b0. If the lowest calibration code is the correct code, the analog will respond with 1'b1, and the algorithm can't sequence to a lower code to look for the transition from 1'b1 to 1'b0. Similarly, if the analog is not responding, it is not possible to sequence to a lower code to detect this. Therefore, even when the calibration function selects this calibration code as valid, this bit will be set.
  [12] CMN_RXCAL_CTRL_12 ro — Current analog comparator response: This is the current state of the analog comparator response signal (cmnda_rescal_comp_rx). This signal is not synchronized, and is provided for diagnostic purposes only.
  [4:0] CMN_RXCAL_CTRL_4_0 ro — Resistor calibration code: This is the calibration code that was determined by the resistor calibration process. The following are the values for the code: 5'b00000: No resistors active 5'b00001: 1 resistor active 5'b00010: 2 resistors active 5'b00011: 3 resistors active ... 5'b01110: 14 resistors active. 5'b01111: 15 resistors active. Note: The most significant bit is the calibration code sign bit, and is always 1'b0 in this application.
